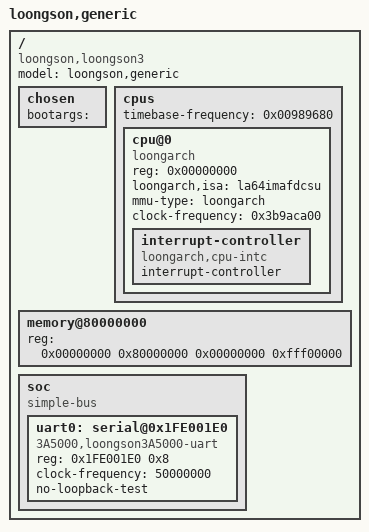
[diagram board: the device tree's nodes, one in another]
/dts-v1/;
/ {
  	compatible = "loongson,loongson3";
  	model = "loongson,generic";
	#address-cells = <2>;
	#size-cells = <2>;
	chosen {
		    bootargs = "";
	};
	
	cpus {
    	#address-cells = <0x00000001>;
    	#size-cells = <0x00000000>;
    	timebase-frequency = <0x00989680>;
   		 cpu@0 {
				device_type = "cpu";
				reg = <0x00000000>;
      			status = "okay";
      			compatible = "loongarch";
      			loongarch,isa = "la64imafdcsu";
      			mmu-type = "loongarch";
      			clock-frequency = <0x3b9aca00>;
      			interrupt-controller {
					  #interrupt-cells = <0x00000001>;
        				interrupt-controller;
        				compatible = "loongarch,cpu-intc";
        				linux,phandle = <0x00000001>;
        				phandle = <0x00000001>;
      			};
    		};
	};

	memory@80000000 {
		device_type = "memory";
		reg = <0x00000000 0x80000000 0x00000000 0xfff00000>;
	};


	soc{
		compatible = "simple-bus";


		uart0: serial@0x1FE001E0 {
			device_type = "serial";
			compatible = "3A5000,loongson3A5000-uart", "ns16550a";
			//compatible = "3A5000,loongson3A5000-uart";
			reg = < 0x1FE001E0 0x8 >;
			clock-frequency = <50000000>;
			status = "okay";
			no-loopback-test;
		};
	};
};
